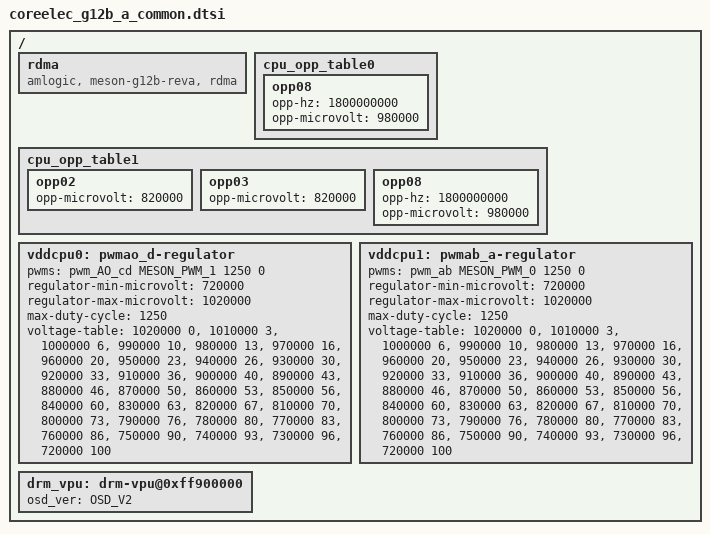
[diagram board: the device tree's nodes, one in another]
/ {
	rdma{
		compatible = "amlogic, meson-g12b-reva, rdma";
	};

	cpu_opp_table0: cpu_opp_table0 {
		opp08 {
			opp-hz = /bits/ 64 <1800000000>;
			opp-microvolt = <980000>;
		};
	};

	cpu_opp_table1: cpu_opp_table1 {
		opp02 {
			opp-microvolt = <820000>;
		};
		opp03 {
			opp-microvolt = <820000>;
		};
		opp08 {
			opp-hz = /bits/ 64 <1800000000>;
			opp-microvolt = <980000>;
		};

		/delete-node/ opp09;
		/delete-node/ opp10;
		/delete-node/ opp11;
		/delete-node/ opp12;
	};

	vddcpu0: pwmao_d-regulator {
		pwms = <&pwm_AO_cd MESON_PWM_1 1250 0>;
		regulator-min-microvolt = <720000>;
		regulator-max-microvolt = <1020000>;
		max-duty-cycle = <1250>;
		/* Voltage Duty-Cycle */
		voltage-table = <1020000 0>,
			<1010000 3>,
			<1000000 6>,
			<990000 10>,
			<980000 13>,
			<970000 16>,
			<960000 20>,
			<950000 23>,
			<940000 26>,
			<930000 30>,
			<920000 33>,
			<910000 36>,
			<900000 40>,
			<890000 43>,
			<880000 46>,
			<870000 50>,
			<860000 53>,
			<850000 56>,
			<840000 60>,
			<830000 63>,
			<820000 67>,
			<810000 70>,
			<800000 73>,
			<790000 76>,
			<780000 80>,
			<770000 83>,
			<760000 86>,
			<750000 90>,
			<740000 93>,
			<730000 96>,
			<720000 100>;
	 };

	vddcpu1: pwmab_a-regulator {
		pwms = <&pwm_ab MESON_PWM_0 1250 0>;
		regulator-min-microvolt = <720000>;
		regulator-max-microvolt = <1020000>;
		max-duty-cycle = <1250>;
		/* Voltage Duty-Cycle */
		voltage-table = <1020000 0>,
			<1010000 3>,
			<1000000 6>,
			<990000 10>,
			<980000 13>,
			<970000 16>,
			<960000 20>,
			<950000 23>,
			<940000 26>,
			<930000 30>,
			<920000 33>,
			<910000 36>,
			<900000 40>,
			<890000 43>,
			<880000 46>,
			<870000 50>,
			<860000 53>,
			<850000 56>,
			<840000 60>,
			<830000 63>,
			<820000 67>,
			<810000 70>,
			<800000 73>,
			<790000 76>,
			<780000 80>,
			<770000 83>,
			<760000 86>,
			<750000 90>,
			<740000 93>,
			<730000 96>,
			<720000 100>;
	 };

	drm_vpu: drm-vpu@0xff900000  {
		osd_ver = /bits/ 8 <OSD_V2>;
	};
};
